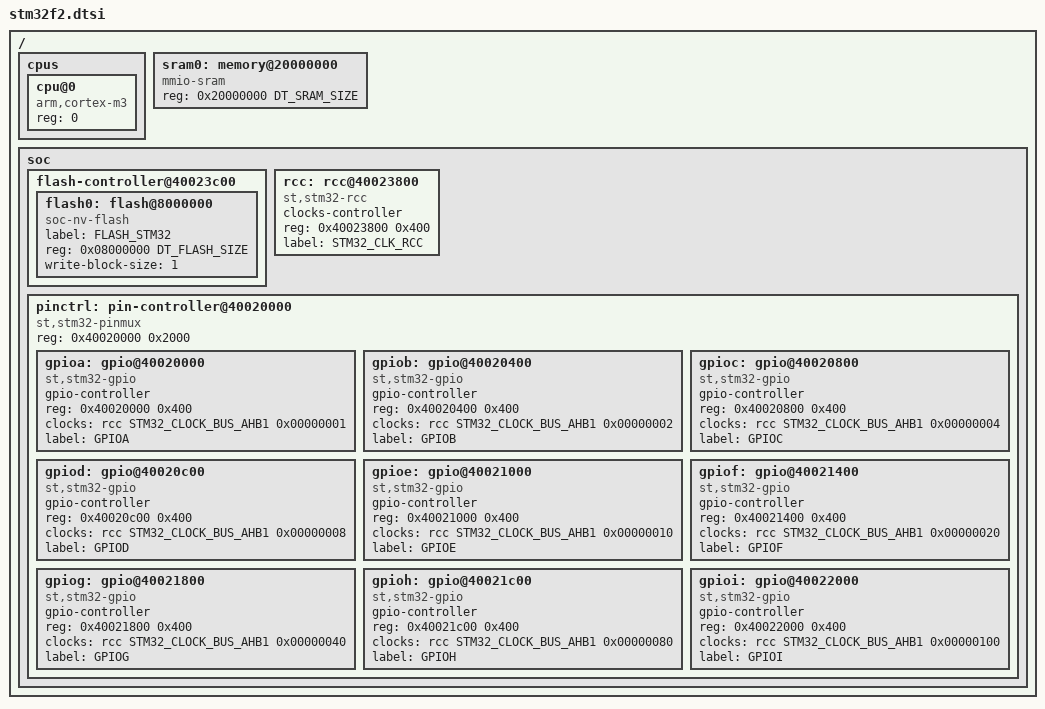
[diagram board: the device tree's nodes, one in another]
/*
 * Copyright (c) 2018 qianfan Zhao
 *
 * SPDX-License-Identifier: Apache-2.0
 */

#include <arm/armv7-m.dtsi>
#include <st/mem.h>
#include <st/stm32f2-pinctrl.dtsi>
#include <dt-bindings/clock/stm32_clock.h>
#include <dt-bindings/gpio/gpio.h>

/ {
	cpus {
		#address-cells = <1>;
		#size-cells = <0>;

		cpu@0 {
			device_type = "cpu";
			compatible = "arm,cortex-m3";
			reg = <0>;
		};
	};

	sram0: memory@20000000 {
		device_type = "memory";
		compatible = "mmio-sram";
		reg = <0x20000000 DT_SRAM_SIZE>;
	};

	soc {
		flash-controller@40023c00 {
			#address-cells = <1>;
			#size-cells = <1>;

			flash0: flash@8000000 {
				compatible = "soc-nv-flash";
				label = "FLASH_STM32";
				reg = <0x08000000 DT_FLASH_SIZE>;

				write-block-size = <1>;
			};
		};

		rcc: rcc@40023800 {
			compatible = "st,stm32-rcc";
			clocks-controller;
			#clock-cells = <2>;
			reg = <0x40023800 0x400>;
			label = "STM32_CLK_RCC";
		};

		pinctrl: pin-controller@40020000 {
			compatible = "st,stm32-pinmux";
			#address-cells = <1>;
			#size-cells = <1>;
			reg = <0x40020000 0x2000>;

			gpioa: gpio@40020000 {
				compatible = "st,stm32-gpio";
				gpio-controller;
				#gpio-cells = <2>;
				reg = <0x40020000 0x400>;
				clocks = <&rcc STM32_CLOCK_BUS_AHB1 0x00000001>;
				label = "GPIOA";
			};

			gpiob: gpio@40020400 {
				compatible = "st,stm32-gpio";
				gpio-controller;
				#gpio-cells = <2>;
				reg = <0x40020400 0x400>;
				clocks = <&rcc STM32_CLOCK_BUS_AHB1 0x00000002>;
				label = "GPIOB";
			};

			gpioc: gpio@40020800 {
				compatible = "st,stm32-gpio";
				gpio-controller;
				#gpio-cells = <2>;
				reg = <0x40020800 0x400>;
				clocks = <&rcc STM32_CLOCK_BUS_AHB1 0x00000004>;
				label = "GPIOC";
			};

			gpiod: gpio@40020c00 {
				compatible = "st,stm32-gpio";
				gpio-controller;
				#gpio-cells = <2>;
				reg = <0x40020c00 0x400>;
				clocks = <&rcc STM32_CLOCK_BUS_AHB1 0x00000008>;
				label = "GPIOD";
			};

			gpioe: gpio@40021000 {
				compatible = "st,stm32-gpio";
				gpio-controller;
				#gpio-cells = <2>;
				reg = <0x40021000 0x400>;
				clocks = <&rcc STM32_CLOCK_BUS_AHB1 0x00000010>;
				label = "GPIOE";
			};

			gpiof: gpio@40021400 {
				compatible = "st,stm32-gpio";
				gpio-controller;
				#gpio-cells = <2>;
				reg = <0x40021400 0x400>;
				clocks = <&rcc STM32_CLOCK_BUS_AHB1 0x00000020>;
				label = "GPIOF";
			};

			gpiog: gpio@40021800 {
				compatible = "st,stm32-gpio";
				gpio-controller;
				#gpio-cells = <2>;
				reg = <0x40021800 0x400>;
				clocks = <&rcc STM32_CLOCK_BUS_AHB1 0x00000040>;
				label = "GPIOG";
			};

			gpioh: gpio@40021c00 {
				compatible = "st,stm32-gpio";
				gpio-controller;
				#gpio-cells = <2>;
				reg = <0x40021c00 0x400>;
				clocks = <&rcc STM32_CLOCK_BUS_AHB1 0x00000080>;
				label = "GPIOH";
			};

			gpioi: gpio@40022000 {
				compatible = "st,stm32-gpio";
				gpio-controller;
				#gpio-cells = <2>;
				reg = <0x40022000 0x400>;
				clocks = <&rcc STM32_CLOCK_BUS_AHB1 0x00000100>;
				label = "GPIOI";
			};
		};
	};
};
